AUTOSAR XML (schema 00050)
standard types defined: Boolean
package /ARRoot
  sender receiver interface AntiPinchStatusSRIF: data-elements=variable-data-prototype=type=Boolean
  trigger interface ExternalTriggerForAntiPinch
    trigger TriggerForAntiPinch
  trigger interface ExternalTriggerForMotor
    trigger TriggerForMotor
  client server interface MotorControlStatusCSIF: client-server-operation=arguments=argument-data-prototype=type=Boolean
  swc implementation MotorControllerImpFile: programming-language=C, behavior=MotorControllerIB
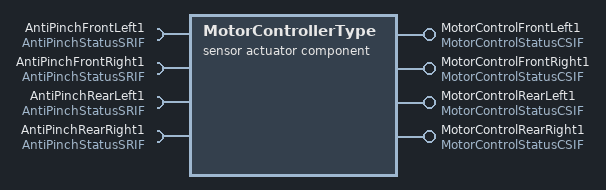
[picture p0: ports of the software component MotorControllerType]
  sensor actuator sw component type MotorControllerType
    4 x require port, all with required-interface=AntiPinchStatusSRIF:
      AntiPinchFrontLeft1
      AntiPinchFrontRight1
      AntiPinchRearLeft1
      AntiPinchRearRight1
    4 x provide port, all with provided-interface=MotorControlStatusCSIF:
      MotorControlFrontLeft1
      MotorControlFrontRight1
      MotorControlRearLeft1
      MotorControlRearRight1
    behavior MotorControllerIB
      8 x runnable:
        AntiPinchFrontLeft1: external-triggering-point=AntiPinchFrontLeft.TriggerForAntiPinch
        AntiPinchFrontRight1: external-triggering-point=AntiPinchFrontRight.TriggerForAntiPinch
        AntiPinchRearLeft1: external-triggering-point=AntiPinchRearLeft.TriggerForAntiPinch
        AntiPinchRearRight1: external-triggering-point=AntiPinchRearRight.TriggerForAntiPinch
        MotorControlFrontLeft1: external-triggering-point=MotorControlFrontLeft1.TriggerForMotor
        MotorControlFrontRight1: external-triggering-point=MotorControlFrontRight1.TriggerForMotor
        MotorControlRearLeft1: external-triggering-point=MotorControlRearLeft1.TriggerForMotor
        MotorControlRearRight1: external-triggering-point=MotorControlRearRight1.TriggerForMotor
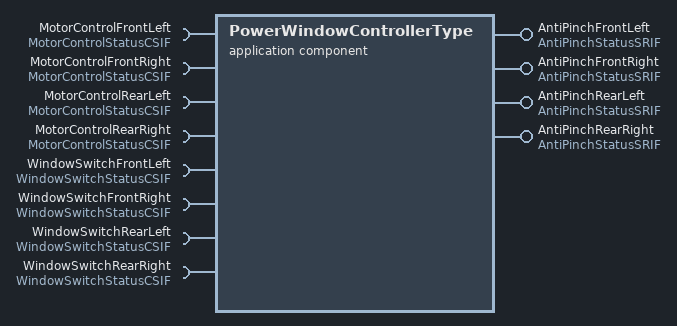
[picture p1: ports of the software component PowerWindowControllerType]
  application sw component type PowerWindowControllerType
    4 x provide port, all with provided-interface=AntiPinchStatusSRIF:
      AntiPinchFrontLeft
      AntiPinchFrontRight
      AntiPinchRearLeft
      AntiPinchRearRight
    8 x require port:
      MotorControlFrontLeft: required-interface=MotorControlStatusCSIF
      MotorControlFrontRight: required-interface=MotorControlStatusCSIF
      MotorControlRearLeft: required-interface=MotorControlStatusCSIF
      MotorControlRearRight: required-interface=MotorControlStatusCSIF
      WindowSwitchFrontLeft: required-interface=WindowSwitchStatusCSIF
      WindowSwitchFrontRight: required-interface=WindowSwitchStatusCSIF
      WindowSwitchRearLeft: required-interface=WindowSwitchStatusCSIF
      WindowSwitchRearRight: required-interface=WindowSwitchStatusCSIF
    behavior PowerWindowIB
      12 x runnable:
        AntiPinchFrontLeftRunnable: variable-access=accessed-variable=/ARRoot/AntiPinchStatusSRIF/
        AntiPinchFrontRightRunnable
          data-write-access:
            access SeatHeatingLeftSoftwareMapping: accessed-variable=/ARRoot/AntiPinchStatusSRIF/
        AntiPinchRearLeftRunnable: variable-access=accessed-variable=/ARRoot/AntiPinchStatusSRIF/
        AntiPinchRearRightRunnable: variable-access=accessed-variable=/ARRoot/AntiPinchStatusSRIF/
        MotorFrontLeftRunnable: synchronous-server-call-point=MotorControlFrontLeft.
        MotorFrontRightRunnable: synchronous-server-call-point=MotorControlFrontRight.
        MotorRearLeftRunnable: synchronous-server-call-point=MotorControlRearLeft.
        MotorRearRightRunnable: synchronous-server-call-point=MotorControlRearRight.
        WindowSwitchFrontLeftRunnable: synchronous-server-call-point=WindowSwitchFrontLeft.
        WindowSwitchFrontRightRunnable: synchronous-server-call-point=WindowSwitchFrontRight.
        WindowSwitchRearLeftRunnable: synchronous-server-call-point=WindowSwitchRearLeft.
        WindowSwitchRearRightRunnable: synchronous-server-call-point=WindowSwitchRearRight.
  swc implementation PowerWindowImpFile: programming-language=C, behavior=PowerWindowIB
  client server interface WindowSwitchStatusCSIF: client-server-operation=arguments=argument-data-prototype={type=Boolean, direction=OUT}
